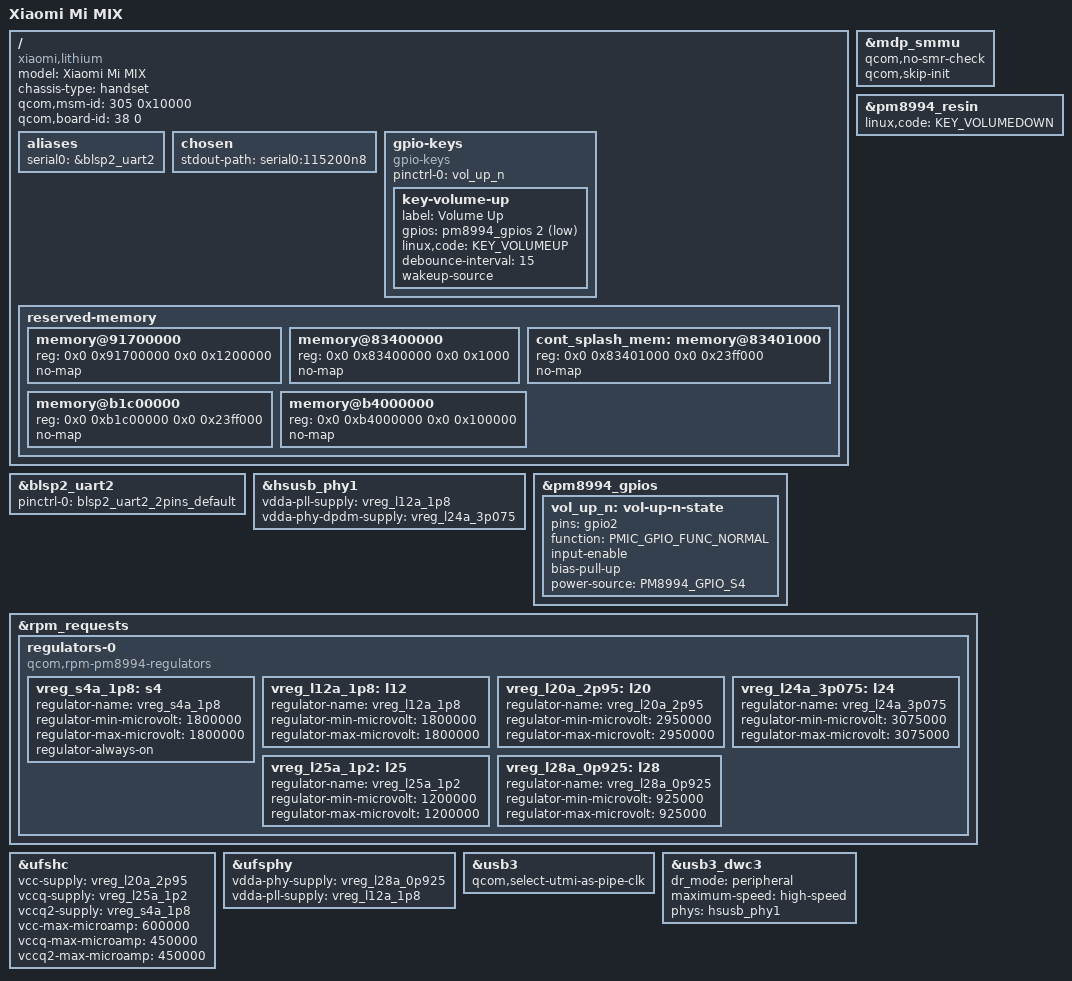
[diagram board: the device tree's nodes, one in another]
// SPDX-License-Identifier: BSD-3-Clause
/*
 * Copyright (c) 2026 Xiaomi Mi MIX Linux port contributors
 */

/dts-v1/;

#include <dt-bindings/gpio/gpio.h>
#include <dt-bindings/input/input.h>
#include <dt-bindings/pinctrl/qcom,pmic-gpio.h>
#include "msm8996pro.dtsi"
#include "pm8994.dtsi"
#include "pmi8994.dtsi"
#include "pmi8996.dtsi"

/*
 * Every value below is traced in research/hardware-map.json to lithium's own
 * stock DTB (boot.img.dtb-5, the one the live unit selects) or the live DT.
 */

/ {
	model = "Xiaomi Mi MIX";
	compatible = "xiaomi,lithium", "qcom,msm8996pro", "qcom,msm8996";
	chassis-type = "handset";

	/* Values selected by the stock bootloader on the observed device. */
	qcom,msm-id = <305 0x10000>;
	qcom,board-id = <38 0>;

	aliases {
		serial0 = &blsp2_uart2;
	};

	chosen {
		stdout-path = "serial0:115200n8";
	};

	gpio-keys {
		compatible = "gpio-keys";

		pinctrl-0 = <&vol_up_n>;
		pinctrl-names = "default";

		key-volume-up {
			label = "Volume Up";
			gpios = <&pm8994_gpios 2 GPIO_ACTIVE_LOW>;
			linux,code = <KEY_VOLUMEUP>;
			debounce-interval = <15>;
			wakeup-source;
		};
	};

	reserved-memory {
		/*
		 * The SoC carveouts cover 0x85800000-0x91700000, all inside the
		 * stock removed/modem/peripheral regions. Reserve the rest of the
		 * stock peripheral region until the PIL layout is mapped.
		 */
		memory@91700000 {
			reg = <0x0 0x91700000 0x0 0x1200000>;
			no-map;
		};

		/* Bootloader splash, still scanned out when Linux starts. */
		memory@83400000 {
			reg = <0x0 0x83400000 0x0 0x1000>;
			no-map;
		};

		cont_splash_mem: memory@83401000 {
			reg = <0x0 0x83401000 0x0 0x23ff000>;
			no-map;
		};

		memory@b1c00000 {
			reg = <0x0 0xb1c00000 0x0 0x23ff000>;
			no-map;
		};

		memory@b4000000 {
			reg = <0x0 0xb4000000 0x0 0x100000>;
			no-map;
		};
	};
};

/* Stock console UART: serial@75b0000 on gpio4/gpio5, ttyHSL0. */
&blsp2_uart2 {
	pinctrl-0 = <&blsp2_uart2_2pins_default>;
	pinctrl-names = "default";

	status = "okay";
};

&hsusb_phy1 {
	vdda-pll-supply = <&vreg_l12a_1p8>;
	vdda-phy-dpdm-supply = <&vreg_l24a_3p075>;

	status = "okay";
};

&mdp_smmu {
	/*
	 * The bootloader's splash is still scanned out through this SMMU when
	 * Linux starts: resetting it hangs the SoC (P5, 2026-10-18: the console
	 * stops right after this SMMU probes, then a reset). As on scorpio, keep
	 * its boot state and keep its power domain on for simple-framebuffer.
	 */
	qcom,no-smr-check;
	qcom,skip-init;
	/delete-property/ power-domains;
};

&pm8994_gpios {
	vol_up_n: vol-up-n-state {
		pins = "gpio2";
		function = PMIC_GPIO_FUNC_NORMAL;
		input-enable;
		bias-pull-up;
		power-source = <PM8994_GPIO_S4>;
	};
};

&pm8994_resin {
	linux,code = <KEY_VOLUMEDOWN>;

	status = "okay";
};

&rpm_requests {
	regulators-0 {
		compatible = "qcom,rpm-pm8994-regulators";

		/* Shared 1.8 V I/O rail; kept on, as on other MSM8996 boards. */
		vreg_s4a_1p8: s4 {
			regulator-name = "vreg_s4a_1p8";
			regulator-min-microvolt = <1800000>;
			regulator-max-microvolt = <1800000>;
			regulator-always-on;
		};

		vreg_l12a_1p8: l12 {
			regulator-name = "vreg_l12a_1p8";
			regulator-min-microvolt = <1800000>;
			regulator-max-microvolt = <1800000>;
		};

		vreg_l20a_2p95: l20 {
			regulator-name = "vreg_l20a_2p95";
			regulator-min-microvolt = <2950000>;
			regulator-max-microvolt = <2950000>;
		};

		vreg_l24a_3p075: l24 {
			regulator-name = "vreg_l24a_3p075";
			regulator-min-microvolt = <3075000>;
			regulator-max-microvolt = <3075000>;
		};

		vreg_l25a_1p2: l25 {
			regulator-name = "vreg_l25a_1p2";
			regulator-min-microvolt = <1200000>;
			regulator-max-microvolt = <1200000>;
		};

		vreg_l28a_0p925: l28 {
			regulator-name = "vreg_l28a_0p925";
			regulator-min-microvolt = <925000>;
			regulator-max-microvolt = <925000>;
		};
	};
};

&ufshc {
	vcc-supply = <&vreg_l20a_2p95>;
	vccq-supply = <&vreg_l25a_1p2>;
	vccq2-supply = <&vreg_s4a_1p8>;

	vcc-max-microamp = <600000>;
	vccq-max-microamp = <450000>;
	vccq2-max-microamp = <450000>;

	status = "okay";
};

&ufsphy {
	vdda-phy-supply = <&vreg_l28a_0p925>;
	vdda-pll-supply = <&vreg_l12a_1p8>;

	status = "okay";
};

&usb3 {
	qcom,select-utmi-as-pipe-clk;

	status = "okay";
};

/*
 * First-boot USB networking: fixed peripheral role on the high-speed PHY.
 * The TUSB320L Type-C controller has no interrupt in the stock DTB, so role
 * switching is not described yet.
 */
&usb3_dwc3 {
	dr_mode = "peripheral";
	maximum-speed = "high-speed";
	phys = <&hsusb_phy1>;
	phy-names = "usb2-phy";
};
